VERSION ""

NS_ :

BS_:

BU_: ECU Dashboard

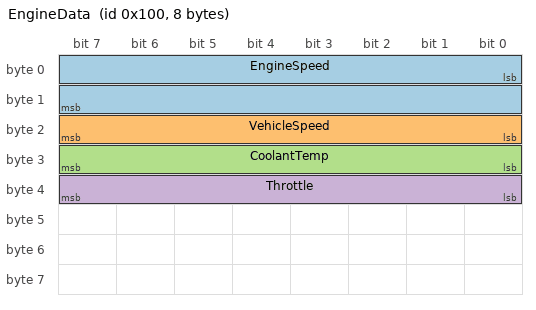
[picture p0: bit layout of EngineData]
BO_ 256 EngineData: 8 ECU
 SG_ EngineSpeed : 0|16@1+ (1,0) [0|8000] "rpm" Dashboard
 SG_ VehicleSpeed : 16|8@1+ (1,0) [0|250] "km/h" Dashboard
 SG_ CoolantTemp : 24|8@1+ (1,-40) [-40|150] "degC" Dashboard
 SG_ Throttle : 32|8@1+ (0.5,0) [0|100] "%" Dashboard

BO_ 512 Lights: 1 Dashboard
 SG_ HeadLight : 0|1@1+ (1,0) [0|1] "" ECU
 SG_ Hazard : 1|1@1+ (1,0) [0|1] "" ECU

BO_ 768 Control: 2 Dashboard
 SG_ EngineOn : 0|1@1+ (1,0) [0|1] "" ECU
 SG_ TargetSpeed : 8|8@1+ (1,0) [0|250] "km/h" ECU

CM_ BO_ 256 "Engine values, sent by the engine control unit";
CM_ BO_ 768 "Commands of the dashboard";
